VERSION "HIPFNNYYYYYYYYYYYYYYYYYYYYYYYYYYNNNNNNNNNN/4/%%%/4/'%**4NNN///"

NS_ :

BS_:

BU_: DisplayPanel GalleyMaster SteamOven CoffeeMaker TrashCompactor
VAL_TABLE_ DIAG_GenErrId_Values 0 "No error" 1 "Hardware" 2 "Software" 3 "Operation" 4 "Interface" 5 "Communication" 6 "External Resources" ;
VAL_TABLE_ DIAG_ErrGravity_Values 5 "Safety" 4 "Failure" 3 "Malfunction" 2 "Warning" 1 "Info" ;
VAL_TABLE_ DIAG_Cmd_Values 4 "SendGAIN_CLASS_msg" 2 "AbortSelfTest" 1 "SelfTestRequest" 0 "NotApplicable" ;
VAL_TABLE_ STO_FlightPhase_Values 12 "Parking/Post-flight" 11 "Taxi in" 10 "Landing" 9 "Approach" 8 "Cruise" 7 "Climb 2nd step" 6 "Climb 1st step" 5 "Take off 3rd step" 4 "Take off 2nd step" 3 "Take off 1st step" 2 "Taxi out" 1 "Parking/Pre-flight" 0 "NotApplicable" ;
VAL_TABLE_ STO_Units_Values 13 "Unit/-s" 12 "Lartge Cup/-s" 11 "Medium Cup/-s" 10 "Little Cup/-s" 9 "Flashes" 8 "Meal/-s" 7 "Fluid Ounces" 6 "Pints" 5 "Gallons" 4 "Liter" 3 "Pound" 2 "Ounces" 1 "kg" 0 "NotApplicable" ;
VAL_TABLE_ STO_Quality_Value 4 "Damaged" 3 "Low" 2 "Medium" 1 "High" 0 "Not applicable" ;
VAL_TABLE_ CSTA_NewState_Value 9 "StandBy Off" 8 "Error" 7 "Maintenance" 6 "Finished" 2 "StandBy On" ;
VAL_TABLE_ CMD_Cmd_Values 22 "Send_GAIN_Class_Msg" 21 "Send_STO_Msg" 20 "Send_CAT_Info_Msg" 4 "Keep warm" 3 "Pause catering process" 2 "Finish catering process" 1 "Start catering process" 0 "Not applicable" ;
VAL_TABLE_ STA_MGCU_StateVal 4 "Error" 3 "Maintenance" 2 "Operational" ;
VAL_TABLE_ AR812MsgCode 28 "STA_GAIN" 26 "STA_MGCU" 24 "DTA" 22 "DIAG" 20 "DIAG_CMD" 18 "PBM" 16 "PBR" 14 "GAIN_PT" 12 "FLIGHT_INFO" 10 "GAIN_CLASS" 8 "STO" 6 "CAT_INFO" 4 "CSTA" 2 "CMD" ;
VAL_TABLE_ DIAG_SpecErrId_Values 50 "Pin programming error" 43 "Phase C loss" 42 "Phase B loss" 41 "Phase A loss" 40 "Phase loss" 31 "Configuration error" 30 "Self-test aborted" 24 "Overflow" 23 "Message sequence interrupted" 22 "Command error" 21 "Invalid message" 20 "Invalid device ID" 15 "Checksum error" 14 "Data transfer denied (already on process)" 13 "File already exists" 12 "Allocation exceeded" 11 "Data transmission counter error" 10 "Data transmission interrupted" 2 "Catering Process Quality Damaged" 1 "Undefined Error" 0 "No error" ;

BO_ 3221225472 VECTOR__INDEPENDENT_SIG_MSG: 0 Vector__XXX
 SG_ PBR_BudgetType : 0|1@1+ (1,0) [0|0] "" Vector__XXX
 SG_ PBR_NominalPB : 0|8@1+ (50,0) [0|12750] "VA" Vector__XXX
 SG_ PBR_NeededTimeWithNominalPB : 0|16@1+ (1,0) [0|0] "sec" Vector__XXX
 SG_ PBR_MinPB : 0|8@1+ (50,0) [0|12750] "VA" Vector__XXX
 SG_ PBR_NeededTimeWithMinPB : 0|16@1+ (1,0) [0|0] "sec" Vector__XXX
 SG_ STA_GAIN_Mode : 0|4@1+ (1,0) [0|0] "" Vector__XXX
 SG_ STA_GAIN_State : 0|4@1+ (1,0) [0|0] "" Vector__XXX
 SG_ STA_GAIN_UsedPB : 0|8@1+ (50,0) [0|12750] "" Vector__XXX
 SG_ STA_GAIN_FallbackPB : 0|8@1+ (1,0) [0|0] "" Vector__XXX
 SG_ STA_GAIN_PBRemainingTime : 0|16@1+ (1,0) [0|0] "" Vector__XXX
 SG_ STA_GAIN_ImplFunc : 0|8@1+ (1,0) [0|0] "" Vector__XXX
 SG_ STA_GAIN_PBudgetType : 0|1@1+ (1,0) [0|0] "" Vector__XXX
 SG_ STA_GAIN_FlightInfoRcvd : 0|1@1+ (1,0) [0|0] "" Vector__XXX
 SG_ STA_GAIN_Mode : 0|4@1+ (1,0) [0|0] "" Vector__XXX
 SG_ STA_GAIN_State : 0|4@1+ (1,0) [0|0] "" Vector__XXX
 SG_ STA_GAIN_UsedPB : 0|8@1+ (50,0) [0|12750] "" Vector__XXX
 SG_ STA_GAIN_FallbackPB : 0|8@1+ (1,0) [0|0] "" Vector__XXX
 SG_ STA_GAIN_PBRemainingTime : 0|16@1+ (1,0) [0|0] "" Vector__XXX
 SG_ STA_GAIN_ImplFunc : 0|8@1+ (1,0) [0|0] "" Vector__XXX
 SG_ STA_GAIN_PBudgetType : 0|1@1+ (1,0) [0|0] "" Vector__XXX
 SG_ STA_GAIN_FlightInfoRcvd : 0|1@1+ (1,0) [0|0] "" Vector__XXX
 SG_ STA_MGCU_State : 0|8@1+ (1,0) [0|0] "" Vector__XXX
 SG_ STA_MGCU_Impl_Func : 0|8@1+ (1,0) [0|0] "" Vector__XXX
 SG_ STA_MGCU_Power_Info_Feeder : 0|5@1+ (1,0) [0|0] "" Vector__XXX
 SG_ STA_MGCU_Power_Info : 0|11@1+ (1,0) [0|0] "" Vector__XXX
 SG_ STA_MGCU_Pwr_Cntrl_Prio : 0|2@1+ (1,0) [0|0] "" Vector__XXX
 SG_ DTA_Descr_DataPacketNr : 0|4@1- (1,0) [0|15] "" Vector__XXX
 SG_ DTA_Descr_HandshakeType : 0|4@1+ (1,0) [0|15] "" Vector__XXX
 SG_ DTA_SrcLevelId : 0|5@1+ (1,0) [0|0] "" Vector__XXX
 SG_ DTA_SrcDeviceId : 0|5@1+ (1,0) [0|0] "" Vector__XXX
 SG_ DTA_Descr_Type : 0|1@1+ (1,0) [0|1] "" Vector__XXX
 SG_ DIAG_Counter : 0|4@1+ (1,0) [0|0] "" Vector__XXX
 SG_ DIAG_ErrGravity : 0|3@1+ (1,0) [0|0] "" Vector__XXX
 SG_ DIAG_GenErrId : 0|8@1+ (1,0) [0|0] "" Vector__XXX
 SG_ DIAG_SpecErrId : 0|8@1+ (1,0) [0|0] "" Vector__XXX
 SG_ DIAG_VendorErrId : 0|8@1+ (1,0) [0|0] "" Vector__XXX
 SG_ DIAG_CMD_Cmd : 0|8@1+ (1,0) [0|0] "" Vector__XXX
 SG_ PBR_BudgetType : 0|1@1+ (1,0) [0|0] "" Vector__XXX
 SG_ PBR_NominalPB : 0|8@1+ (50,0) [0|12750] "VA" Vector__XXX
 SG_ PBR_NeededTimeWithNominalPB : 0|16@1+ (1,0) [0|0] "sec" Vector__XXX
 SG_ PBR_MinPB : 0|8@1+ (50,0) [0|12750] "VA" Vector__XXX
 SG_ PBR_NeededTimeWithMinPB : 0|16@1+ (1,0) [0|0] "sec" Vector__XXX
 SG_ GAIN_PT_StandByPt : 0|8@1+ (5,0) [0|1275] "VA" Vector__XXX
 SG_ GAIN_PT_MaxPt : 0|8@1+ (50,0) [0|0] "VA" Vector__XXX
 SG_ GAIN_PT_MinPt : 0|8@1+ (50,0) [0|12750] "VA" Vector__XXX
 SG_ GAIN_PT_FallBackPt : 0|8@1+ (50,0) [0|12750] "VA" Vector__XXX
 SG_ FLIGHT_INFO_Year : 0|8@1+ (1,2000) [2000|2255] "" Vector__XXX
 SG_ FLIGHT_INFO_Month : 0|4@1+ (1,0) [0|0] "" Vector__XXX
 SG_ FLIGHT_INFO_Day : 0|5@1+ (1,0) [0|0] "" Vector__XXX
 SG_ FLIGHT_INFO_Hour : 0|5@1+ (1,0) [0|0] "" Vector__XXX
 SG_ FLIGHT_INFO_Min : 0|6@1+ (1,0) [0|0] "" Vector__XXX
 SG_ FLIGHT_INFO_Sec : 0|5@1+ (1,0) [0|0] "" Vector__XXX
 SG_ FLIGHT_INFO_FlightPhase : 0|4@1+ (1,0) [0|0] "" Vector__XXX
 SG_ GAIN_CLASS_DevClass : 0|5@1+ (1,0) [0|0] "" Vector__XXX
 SG_ GAIN_CLASS_DevGroup : 0|5@1+ (1,0) [0|0] "" Vector__XXX
 SG_ STO_Quality : 0|3@1+ (1,0) [0|0] "" Vector__XXX
 SG_ STO_Units : 0|5@1+ (1,0) [0|31] "" Vector__XXX
 SG_ STO_Quantity : 0|8@1+ (1,0) [0|0] "" Vector__XXX
 SG_ STO_FoodTypeDescr1 : 0|8@1+ (1,0) [0|0] "" Vector__XXX
 SG_ STO_FoodTypeDescr2 : 0|8@1+ (1,0) [0|0] "" Vector__XXX
 SG_ STO_FoodTypeDescr3 : 0|8@1+ (1,0) [0|0] "" Vector__XXX
 SG_ STO_FoodTypeDescr4 : 0|8@1+ (1,0) [0|0] "" Vector__XXX
 SG_ STO_Cluster : 0|4@1+ (1,0) [0|0] "" Vector__XXX
 SG_ CAT_Info_CateringProcess : 0|8@1+ (1,0) [0|0] "" Vector__XXX
 SG_ CAT_Info_SelectCaterProgram : 0|5@1+ (1,0) [0|0] "" Vector__XXX
 SG_ CAT_Info_PhysUnit : 0|3@1+ (1,0) [0|0] "" Vector__XXX
 SG_ CAT_Info_PhysUnit : 0|3@1+ (1,0) [0|0] "" Vector__XXX
 SG_ CAT_Info_PhysProp1 : 0|16@1+ (1,0) [0|0] "" Vector__XXX
 SG_ CAT_Info_PhysProp1 : 0|16@1+ (1,0) [0|0] "" Vector__XXX
 SG_ CAT_Info_Cluster : 0|4@1+ (1,0) [0|0] "" Vector__XXX
 SG_ CSTA_Reset : 0|1@1+ (1,0) [0|0] "" Vector__XXX
 SG_ CSTA_PowerCntrlMode : 0|3@1+ (1,0) [0|0] "" Vector__XXX
 SG_ CSTA_NewState : 0|4@1+ (1,0) [0|0] "" Vector__XXX
 SG_ CMD_Command : 0|5@1+ (1,0) [0|0] "" Vector__XXX
 SG_ CMD_SetCateringProgram : 0|5@1+ (1,0) [0|0] "" Vector__XXX
 SG_ CMD_PhysUnit1 : 0|3@1+ (1,0) [0|0] "" Vector__XXX
 SG_ CMD_PhysUnit2 : 0|3@1+ (1,0) [0|0] "" Vector__XXX
 SG_ CMD_PhysProperty1 : 0|16@1+ (1,0) [0|0] "" Vector__XXX
 SG_ CMD_PhysProperty2 : 0|16@1+ (1,0) [0|0] "" Vector__XXX
 SG_ CMD_Cluster : 0|4@1+ (1,0) [0|0] "" Vector__XXX

BO_ 2358265349 PBM_ToTrashCompactor: 8 Vector__XXX
 SG_ PBM_PBMax : 0|8@1+ (50,0) [0|12750] "VA" Vector__XXX
 SG_ PBM_Time : 8|16@1+ (1,0) [0|0] "" Vector__XXX

BO_ 2358264837 PBM_ToSteamOven: 8 Vector__XXX
 SG_ PBM_PBMax : 0|8@1+ (50,0) [0|12750] "VA" Vector__XXX
 SG_ PBM_Time : 8|16@1+ (1,0) [0|0] "" Vector__XXX

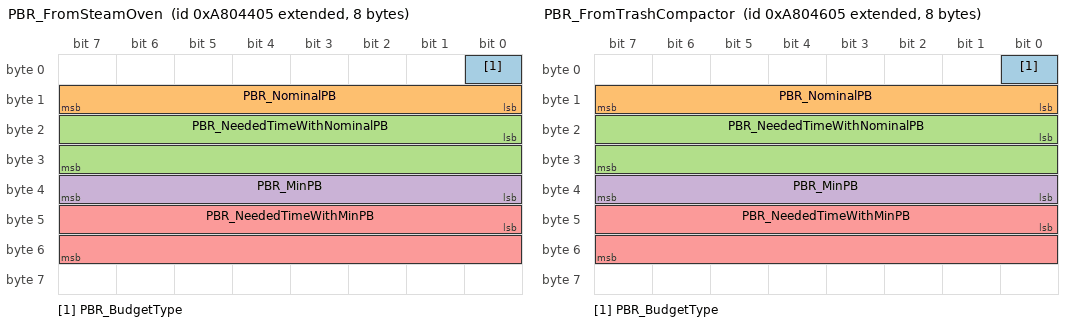
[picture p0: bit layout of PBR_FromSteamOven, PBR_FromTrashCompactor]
BO_ 2323661829 PBR_FromSteamOven: 8 Vector__XXX
 SG_ PBR_BudgetType : 0|1@1+ (1,0) [0|0] "" Vector__XXX
 SG_ PBR_NominalPB : 8|8@1+ (50,0) [0|12750] "VA" Vector__XXX
 SG_ PBR_NeededTimeWithNominalPB : 16|16@1+ (1,0) [0|0] "sec" Vector__XXX
 SG_ PBR_MinPB : 32|8@1+ (50,0) [0|12750] "VA" Vector__XXX
 SG_ PBR_NeededTimeWithMinPB : 40|16@1+ (1,0) [0|0] "sec" Vector__XXX

BO_ 2323662341 PBR_FromTrashCompactor: 8 Vector__XXX
 SG_ PBR_BudgetType : 0|1@1+ (1,0) [0|0] "" Vector__XXX
 SG_ PBR_NominalPB : 8|8@1+ (50,0) [0|12750] "VA" Vector__XXX
 SG_ PBR_NeededTimeWithNominalPB : 16|16@1+ (1,0) [0|0] "sec" Vector__XXX
 SG_ PBR_MinPB : 32|8@1+ (50,0) [0|12750] "VA" Vector__XXX
 SG_ PBR_NeededTimeWithMinPB : 40|16@1+ (1,0) [0|0] "sec" Vector__XXX

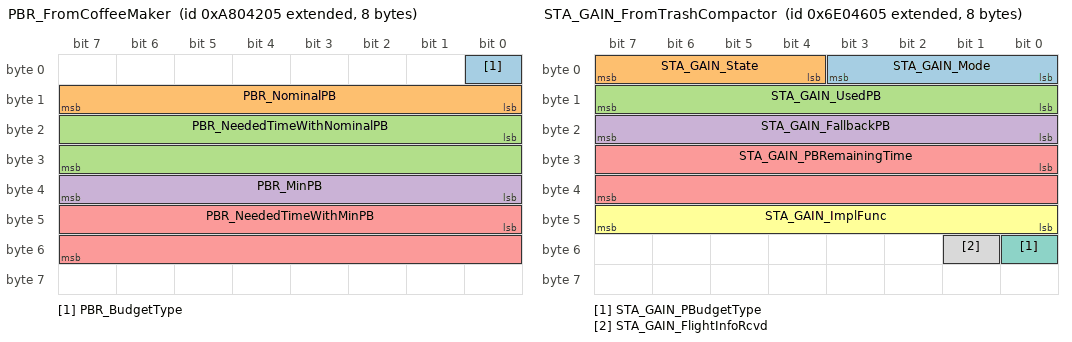
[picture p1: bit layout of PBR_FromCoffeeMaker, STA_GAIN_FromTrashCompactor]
BO_ 2323661317 PBR_FromCoffeeMaker: 8 Vector__XXX
 SG_ PBR_BudgetType : 0|1@1+ (1,0) [0|0] "" Vector__XXX
 SG_ PBR_NominalPB : 8|8@1+ (50,0) [0|12750] "VA" Vector__XXX
 SG_ PBR_NeededTimeWithNominalPB : 16|16@1+ (1,0) [0|0] "sec" Vector__XXX
 SG_ PBR_MinPB : 32|8@1+ (50,0) [0|12750] "VA" Vector__XXX
 SG_ PBR_NeededTimeWithMinPB : 40|16@1+ (1,0) [0|0] "sec" Vector__XXX

BO_ 2262844933 STA_GAIN_FromTrashCompactor: 8 TrashCompactor
 SG_ STA_GAIN_Mode : 0|4@1+ (1,0) [0|0] "" Vector__XXX
 SG_ STA_GAIN_State : 4|4@1+ (1,0) [0|0] "" Vector__XXX
 SG_ STA_GAIN_UsedPB : 8|8@1+ (50,0) [0|12750] "" Vector__XXX
 SG_ STA_GAIN_FallbackPB : 16|8@1+ (1,0) [0|0] "" Vector__XXX
 SG_ STA_GAIN_PBRemainingTime : 24|16@1+ (1,0) [0|0] "" Vector__XXX
 SG_ STA_GAIN_ImplFunc : 40|8@1+ (1,0) [0|0] "" Vector__XXX
 SG_ STA_GAIN_PBudgetType : 48|1@1+ (1,0) [0|0] "" Vector__XXX
 SG_ STA_GAIN_FlightInfoRcvd : 49|1@1+ (1,0) [0|0] "" Vector__XXX

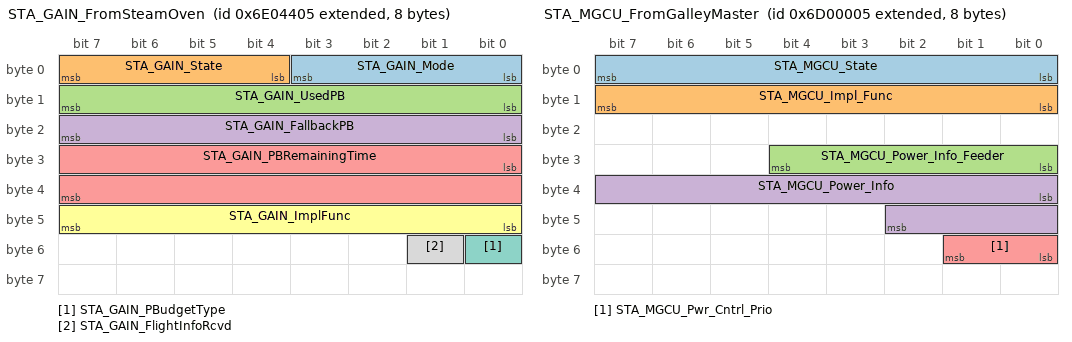
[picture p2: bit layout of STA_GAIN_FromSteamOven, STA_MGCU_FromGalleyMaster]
BO_ 2262844421 STA_GAIN_FromSteamOven: 8 SteamOven
 SG_ STA_GAIN_Mode : 0|4@1+ (1,0) [0|0] "" Vector__XXX
 SG_ STA_GAIN_State : 4|4@1+ (1,0) [0|0] "" Vector__XXX
 SG_ STA_GAIN_UsedPB : 8|8@1+ (50,0) [0|12750] "" Vector__XXX
 SG_ STA_GAIN_FallbackPB : 16|8@1+ (1,0) [0|0] "" Vector__XXX
 SG_ STA_GAIN_PBRemainingTime : 24|16@1+ (1,0) [0|0] "" Vector__XXX
 SG_ STA_GAIN_ImplFunc : 40|8@1+ (1,0) [0|0] "" Vector__XXX
 SG_ STA_GAIN_PBudgetType : 48|1@1+ (1,0) [0|0] "" Vector__XXX
 SG_ STA_GAIN_FlightInfoRcvd : 49|1@1+ (1,0) [0|0] "" Vector__XXX

BO_ 2261778437 STA_MGCU_FromGalleyMaster: 8 GalleyMaster
 SG_ STA_MGCU_State : 0|8@1+ (1,0) [0|0] "" Vector__XXX
 SG_ STA_MGCU_Impl_Func : 8|8@1+ (1,0) [0|0] "" Vector__XXX
 SG_ STA_MGCU_Power_Info_Feeder : 24|5@1+ (1,0) [0|0] "" Vector__XXX
 SG_ STA_MGCU_Power_Info : 32|11@1+ (1,0) [0|0] "" Vector__XXX
 SG_ STA_MGCU_Pwr_Cntrl_Prio : 48|2@1+ (1,0) [0|0] "" Vector__XXX

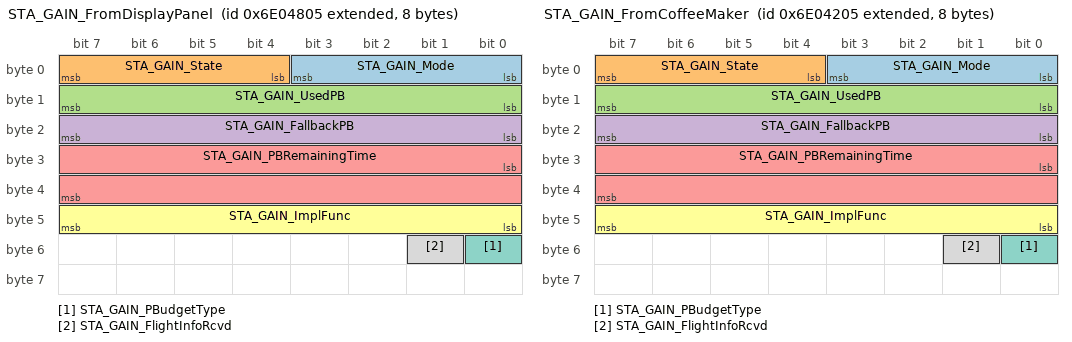
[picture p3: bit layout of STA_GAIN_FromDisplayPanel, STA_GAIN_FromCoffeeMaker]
BO_ 2262845445 STA_GAIN_FromDisplayPanel: 8 DisplayPanel
 SG_ STA_GAIN_Mode : 0|4@1+ (1,0) [0|0] "" Vector__XXX
 SG_ STA_GAIN_State : 4|4@1+ (1,0) [0|0] "" Vector__XXX
 SG_ STA_GAIN_UsedPB : 8|8@1+ (50,0) [0|12750] "" Vector__XXX
 SG_ STA_GAIN_FallbackPB : 16|8@1+ (1,0) [0|0] "" Vector__XXX
 SG_ STA_GAIN_PBRemainingTime : 24|16@1+ (1,0) [0|0] "" Vector__XXX
 SG_ STA_GAIN_ImplFunc : 40|8@1+ (1,0) [0|0] "" Vector__XXX
 SG_ STA_GAIN_PBudgetType : 48|1@1+ (1,0) [0|0] "" Vector__XXX
 SG_ STA_GAIN_FlightInfoRcvd : 49|1@1+ (1,0) [0|0] "" Vector__XXX

BO_ 2262843909 STA_GAIN_FromCoffeeMaker: 8 CoffeeMaker
 SG_ STA_GAIN_Mode : 0|4@1+ (1,0) [0|0] "" Vector__XXX
 SG_ STA_GAIN_State : 4|4@1+ (1,0) [0|0] "" Vector__XXX
 SG_ STA_GAIN_UsedPB : 8|8@1+ (50,0) [0|12750] "" Vector__XXX
 SG_ STA_GAIN_FallbackPB : 16|8@1+ (1,0) [0|0] "" Vector__XXX
 SG_ STA_GAIN_PBRemainingTime : 24|16@1+ (1,0) [0|0] "" Vector__XXX
 SG_ STA_GAIN_ImplFunc : 40|8@1+ (1,0) [0|0] "" Vector__XXX
 SG_ STA_GAIN_PBudgetType : 48|1@1+ (1,0) [0|0] "" Vector__XXX
 SG_ STA_GAIN_FlightInfoRcvd : 49|1@1+ (1,0) [0|0] "" Vector__XXX

BO_ 2358264325 PBM_ToCoffeeMaker: 8 Vector__XXX
 SG_ PBM_PBMax : 0|8@1+ (50,0) [0|12750] "VA" Vector__XXX
 SG_ PBM_Time : 8|16@1+ (1,0) [0|0] "" Vector__XXX

EV_ SteamOven_PowerUsed: 0 [0|0] "" 0 1 DUMMY_NODE_VECTOR0 Vector__XXX;

EV_ CoffeeMaker_PowerUsed: 0 [0|0] "" 0 2 DUMMY_NODE_VECTOR0 Vector__XXX;

EV_ CoffeeMaker_TempCurrent: 1 [0|0] "" 0 3 DUMMY_NODE_VECTOR0 Vector__XXX;

EV_ SteamOven_TimeText: 0 [0|0] "" 0 4 DUMMY_NODE_VECTOR8000 Vector__XXX;

EV_ SteamOven_TempCurrent: 1 [0|0] "" 0 5 DUMMY_NODE_VECTOR0 Vector__XXX;

EV_ SteamOven_Time: 0 [0|0] "" 0 6 DUMMY_NODE_VECTOR0 Vector__XXX;

EV_ SteamOven_Insert: 0 [0|0] "" 0 7 DUMMY_NODE_VECTOR0 Vector__XXX;

EV_ TrashCompactor_Insert: 0 [0|0] "" 0 8 DUMMY_NODE_VECTOR0 Vector__XXX;

EV_ CoffeeMaker_Insert: 0 [0|0] "" 0 9 DUMMY_NODE_VECTOR0 Vector__XXX;

EV_ TrashCompactor_Trash: 0 [0|0] "" 0 10 DUMMY_NODE_VECTOR0 Vector__XXX;

EV_ SteamOven_Meal: 0 [0|0] "" 0 11 DUMMY_NODE_VECTOR0 Vector__XXX;

EV_ CoffeeMaker_Pot: 0 [0|0] "" 0 12 DUMMY_NODE_VECTOR0 Vector__XXX;

EV_ TrashCompactor_Device: 0 [0|0] "" 0 13 DUMMY_NODE_VECTOR0 Vector__XXX;

EV_ TrashCompactor_Feeder: 0 [0|0] "" 0 14 DUMMY_NODE_VECTOR0 Vector__XXX;

EV_ SteamOven_Device: 0 [0|0] "" 0 15 DUMMY_NODE_VECTOR0 Vector__XXX;

EV_ SteamOven_Feeder: 0 [0|0] "" 0 16 DUMMY_NODE_VECTOR0 Vector__XXX;

EV_ DisplayPanel_Device: 0 [0|0] "" 0 17 DUMMY_NODE_VECTOR0 Vector__XXX;

EV_ DisplayPanel_Feeder: 0 [0|0] "" 0 18 DUMMY_NODE_VECTOR0 Vector__XXX;

EV_ CoffeeMaker_Device: 0 [0|0] "" 0 19 DUMMY_NODE_VECTOR0 Vector__XXX;

EV_ CoffeeMaker_Feeder: 0 [0|0] "" 0 20 DUMMY_NODE_VECTOR0 Vector__XXX;

EV_ DisplayPanel_Esc: 0 [0|0] "" 0 21 DUMMY_NODE_VECTOR0 Vector__XXX;

EV_ DisplayPanel_OK: 0 [0|0] "" 0 22 DUMMY_NODE_VECTOR0 Vector__XXX;

EV_ DisplayPanel_Next: 0 [0|0] "" 0 23 DUMMY_NODE_VECTOR0 Vector__XXX;

EV_ DisplayPanel_Back: 0 [0|0] "" 0 24 DUMMY_NODE_VECTOR0 Vector__XXX;

EV_ DisplayPanel_Out: 0 [0|0] "" 0 25 DUMMY_NODE_VECTOR8000 Vector__XXX;

EV_ CoffeeMaker_ColdWater: 0 [0|0] "" 0 26 DUMMY_NODE_VECTOR0 Vector__XXX;

EV_ CoffeeMaker_HotWater: 0 [0|0] "" 0 27 DUMMY_NODE_VECTOR0 Vector__XXX;

EV_ CoffeeMaker_HotPlateOn: 0 [0|0] "" 0 28 DUMMY_NODE_VECTOR0 Vector__XXX;

EV_ CoffeeMaker_Brew: 0 [0|0] "" 0 29 DUMMY_NODE_VECTOR0 Vector__XXX;

EV_ CoffeeMaker_Power: 0 [0|0] "" 0 30 DUMMY_NODE_VECTOR0 Vector__XXX;

EV_ CoffeeMaker_Fault: 0 [0|0] "" 0 31 DUMMY_NODE_VECTOR0 Vector__XXX;

EV_ CoffeeMaker_Serve: 0 [0|0] "" 0 32 DUMMY_NODE_VECTOR0 Vector__XXX;

EV_ CoffeeMaker_On: 0 [0|0] "" 0 33 DUMMY_NODE_VECTOR0 Vector__XXX;

EV_ SteamOven_Temp: 0 [0|0] "" 50 34 DUMMY_NODE_VECTOR0 Vector__XXX;

EV_ SteamOven_Power: 0 [0|0] "" 0 35 DUMMY_NODE_VECTOR0 Vector__XXX;

EV_ SteamOven_Fault: 0 [0|0] "" 0 36 DUMMY_NODE_VECTOR0 Vector__XXX;

EV_ SteamOven_Serve: 0 [0|0] "" 0 37 DUMMY_NODE_VECTOR0 Vector__XXX;

EV_ SteamOven_On: 0 [0|0] "" 0 38 DUMMY_NODE_VECTOR0 Vector__XXX;

EV_ TrashCompactor_Power: 0 [0|0] "" 0 39 DUMMY_NODE_VECTOR0 Vector__XXX;

EV_ TrashCompactor_Warning: 0 [0|0] "" 0 40 DUMMY_NODE_VECTOR0 Vector__XXX;

EV_ TrashCompactor_Fault: 0 [0|0] "" 0 41 DUMMY_NODE_VECTOR0 Vector__XXX;

EV_ TrashCompactor_On: 0 [0|0] "" 0 42 DUMMY_NODE_VECTOR0 Vector__XXX;

CM_ BO_ 3221225472 "This is a message for not used signals, created by Vector CANdb++ DBC OLE DB Provider.";
BA_DEF_ BU_  "GAINCFG12_1_2_GAIN_COUNTER_THRES" HEX 0 255;
BA_DEF_ BU_  "GAINCFG12_1_1_GAIN_COUNTER_DELTA" HEX 0 255;
BA_DEF_ BU_  "GAINCFG12_1_0_GAIN_COUNTER_DELTA" HEX 0 255;
BA_DEF_ BU_  "MGCUCFG12_0_2_MGCU_COUNTER_THRES" HEX 0 255;
BA_DEF_ BU_  "MGCUCFG12_0_1_MGCU_COUNTER_DELTA" HEX 0 255;
BA_DEF_ BU_  "MGCUCFG12_0_0_MGCU_COUNTER_DELTA" HEX 0 255;
BA_DEF_ BU_  "GAINCFG11_1_1_DECENTRALIZED_RAND" HEX 0 65535;
BA_DEF_ BU_  "GAINCFG11_1_0_DECENTRALIZED_RAND" HEX 0 65535;
BA_DEF_ BU_  "GAINCFG11_0_1_DECENTRALIZED_SYNC" HEX 0 65535;
BA_DEF_ BU_  "GAINCFG11_0_0_DECENTRALIZED_SYNC" HEX 0 65535;
BA_DEF_ BU_  "MGCUCFG10_8_2_INHIBIT_TIMER_STA_" HEX 0 65535;
BA_DEF_ BU_  "MGCUCFG10_8_1_TIMER_STA_TIMEOUT_" HEX 0 65535;
BA_DEF_ BU_  "MGCUCFG10_8_0_TIMER_STA_MGCU" HEX 0 65535;
BA_DEF_ BU_  "MGCUCFG10_7_0_INHIBIT_TIMER_DIAG" HEX 0 65535;
BA_DEF_ BU_  "MGCUCFG10_6_0_INHIBIT_TIMER_PBM" HEX 0 65535;
BA_DEF_ BU_  "MGCUCFG10_5_0_INHIBIT_TIMER_FLIG" HEX 0 65535;
BA_DEF_ BU_  "MGCUCFG10_4_0_INHIBIT_TIMER_CSTA" HEX 0 65535;
BA_DEF_ BU_  "MGCUCFG10_3_0_INHIBIT_TIMER_CMD" HEX 0 65535;
BA_DEF_ BU_  "MGCUCFG10_2_0_SEQUENCE_TIMEOUT_T" HEX 0 65535;
BA_DEF_ BU_  "MGCUCFG10_1_0_INHIBIT_TIMER_DTA" HEX 0 65535;
BA_DEF_ BU_  "MGCUCFG10_0_0_INHIBIT_TIMER_DIAG" HEX 0 65535;
BA_DEF_ BU_  "GAINCFG9_9_2_INHIBIT_TIMER_STA_G" HEX 0 65535;
BA_DEF_ BU_  "GAINCFG9_9_1_TIMER_STA_TIMEOUT_G" HEX 0 65535;
BA_DEF_ BU_  "GAINCFG9_9_0_TIMER_STA_GAIN" HEX 0 65535;
BA_DEF_ BU_  "GAINCFG9_8_0_INHIBIT_TIMER_PBR" HEX 0 65535;
BA_DEF_ BU_  "GAINCFG9_7_0_INHIBIT_TIMER_GAIN_" HEX 0 65535;
BA_DEF_ BU_  "GAINCFG9_6_0_FLIGHT_INFO_RECEIVE" HEX 0 65535;
BA_DEF_ BU_  "GAINCFG9_5_0_INHIBIT_TIMER_GAIN_" HEX 0 65535;
BA_DEF_ BU_  "GAINCFG9_4_0_INHIBIT_TIMER_STO" HEX 0 65535;
BA_DEF_ BU_  "GAINCFG9_3_0_INHIBIT_TIMER_CAT_I" HEX 0 65535;
BA_DEF_ BU_  "GAINCFG9_2_0_SEQUENCE_TIMEOUT_TI" HEX 0 65535;
BA_DEF_ BU_  "GAINCFG7_X_6_SIGN_PHYSICAL_UNIT_" ENUM  "plus","minus";
BA_DEF_ BU_  "GAINCFG7_X_3_SIGN_PHYSICAL_UNIT_" ENUM  "plus","minus";
BA_DEF_ BU_  "GAINCFG5_3_0_DEVICE_CLASS" ENUM  "Specific (Other)","Oven","Beverage Maker","Refrigerator","Waste Handling","Reserved";
BA_DEF_ BU_  "GAINCFG5_2_0_DEVICE_NUMBER" HEX 0 31;
BA_DEF_ BU_  "GAINCFG5_1_0_FEEDER_NUMBER" HEX 0 31;
BA_DEF_ BU_  "GAINCFG5_0_0_FALLBACK_TYPE" ENUM  "Secondary","Primary";
BA_DEF_ BU_  "GAINCFG3_3_0_STANDBY_POWER_THRES" INT 0 12750;
BA_DEF_ BU_  "GAINCFG3_2_0_MINIMUM_POWER_BUDGE" INT 0 12750;
BA_DEF_ BU_  "GAINCFG3_1_0_FALLBACK_POWER_THRE" INT 0 12750;
BA_DEF_ BU_  "GAINCFG3_0_0_MAXIMUM_POWER_BUDGE" INT 0 12750;
BA_DEF_ BU_  "CFG2_1_0_CENTRALIZED_POWER_CONTR" ENUM  "no","yes";
BA_DEF_ BU_  "GAINCFG1_0_0_DEVICE_STANDARD" ENUM  "Reserved","ARINC","ATLAS","KSSU","Reserved","Reserved","Reserved","Reserved","Reserved","Reserved","Reserved","Reserved","Reserved","Reserved","Reserved","Reserved";
BA_DEF_  "ProtocolType" STRING ;
BA_DEF_  "BusType" STRING ;
BA_DEF_DEF_  "GAINCFG12_1_2_GAIN_COUNTER_THRES" 1;
BA_DEF_DEF_  "GAINCFG12_1_1_GAIN_COUNTER_DELTA" 1;
BA_DEF_DEF_  "GAINCFG12_1_0_GAIN_COUNTER_DELTA" 1;
BA_DEF_DEF_  "MGCUCFG12_0_2_MGCU_COUNTER_THRES" 1;
BA_DEF_DEF_  "MGCUCFG12_0_1_MGCU_COUNTER_DELTA" 1;
BA_DEF_DEF_  "MGCUCFG12_0_0_MGCU_COUNTER_DELTA" 1;
BA_DEF_DEF_  "GAINCFG11_1_1_DECENTRALIZED_RAND" 200;
BA_DEF_DEF_  "GAINCFG11_1_0_DECENTRALIZED_RAND" 50;
BA_DEF_DEF_  "GAINCFG11_0_1_DECENTRALIZED_SYNC" 1000;
BA_DEF_DEF_  "GAINCFG11_0_0_DECENTRALIZED_SYNC" 1000;
BA_DEF_DEF_  "MGCUCFG10_8_2_INHIBIT_TIMER_STA_" 1000;
BA_DEF_DEF_  "MGCUCFG10_8_1_TIMER_STA_TIMEOUT_" 2200;
BA_DEF_DEF_  "MGCUCFG10_8_0_TIMER_STA_MGCU" 2000;
BA_DEF_DEF_  "MGCUCFG10_7_0_INHIBIT_TIMER_DIAG" 1000;
BA_DEF_DEF_  "MGCUCFG10_6_0_INHIBIT_TIMER_PBM" 1000;
BA_DEF_DEF_  "MGCUCFG10_5_0_INHIBIT_TIMER_FLIG" 1000;
BA_DEF_DEF_  "MGCUCFG10_4_0_INHIBIT_TIMER_CSTA" 1000;
BA_DEF_DEF_  "MGCUCFG10_3_0_INHIBIT_TIMER_CMD" 1000;
BA_DEF_DEF_  "MGCUCFG10_2_0_SEQUENCE_TIMEOUT_T" 5000;
BA_DEF_DEF_  "MGCUCFG10_1_0_INHIBIT_TIMER_DTA" 50;
BA_DEF_DEF_  "MGCUCFG10_0_0_INHIBIT_TIMER_DIAG" 1000;
BA_DEF_DEF_  "GAINCFG9_9_2_INHIBIT_TIMER_STA_G" 1000;
BA_DEF_DEF_  "GAINCFG9_9_1_TIMER_STA_TIMEOUT_G" 2200;
BA_DEF_DEF_  "GAINCFG9_9_0_TIMER_STA_GAIN" 2000;
BA_DEF_DEF_  "GAINCFG9_8_0_INHIBIT_TIMER_PBR" 1000;
BA_DEF_DEF_  "GAINCFG9_7_0_INHIBIT_TIMER_GAIN_" 1000;
BA_DEF_DEF_  "GAINCFG9_6_0_FLIGHT_INFO_RECEIVE" 6200;
BA_DEF_DEF_  "GAINCFG9_5_0_INHIBIT_TIMER_GAIN_" 6000;
BA_DEF_DEF_  "GAINCFG9_4_0_INHIBIT_TIMER_STO" 6000;
BA_DEF_DEF_  "GAINCFG9_3_0_INHIBIT_TIMER_CAT_I" 1000;
BA_DEF_DEF_  "GAINCFG9_2_0_SEQUENCE_TIMEOUT_TI" 5000;
BA_DEF_DEF_  "GAINCFG7_X_6_SIGN_PHYSICAL_UNIT_" "plus";
BA_DEF_DEF_  "GAINCFG7_X_3_SIGN_PHYSICAL_UNIT_" "plus";
BA_DEF_DEF_  "GAINCFG5_3_0_DEVICE_CLASS" "Specific (Other)";
BA_DEF_DEF_  "GAINCFG5_2_0_DEVICE_NUMBER" 0;
BA_DEF_DEF_  "GAINCFG5_1_0_FEEDER_NUMBER" 0;
BA_DEF_DEF_  "GAINCFG5_0_0_FALLBACK_TYPE" "Secondary";
BA_DEF_DEF_  "GAINCFG3_3_0_STANDBY_POWER_THRES" 0;
BA_DEF_DEF_  "GAINCFG3_2_0_MINIMUM_POWER_BUDGE" 0;
BA_DEF_DEF_  "GAINCFG3_1_0_FALLBACK_POWER_THRE" 0;
BA_DEF_DEF_  "GAINCFG3_0_0_MAXIMUM_POWER_BUDGE" 0;
BA_DEF_DEF_  "CFG2_1_0_CENTRALIZED_POWER_CONTR" "no";
BA_DEF_DEF_  "GAINCFG1_0_0_DEVICE_STANDARD" "ARINC";
BA_DEF_DEF_  "ProtocolType" "ARINC812";
BA_DEF_DEF_  "BusType" "CAN";
BA_ "GAINCFG5_2_0_DEVICE_NUMBER" BU_ DisplayPanel 4;
BA_ "GAINCFG5_1_0_FEEDER_NUMBER" BU_ DisplayPanel 1;
BA_ "GAINCFG3_0_0_MAXIMUM_POWER_BUDGE" BU_ SteamOven 2960;
BA_ "GAINCFG3_1_0_FALLBACK_POWER_THRE" BU_ SteamOven 2960;
BA_ "GAINCFG3_2_0_MINIMUM_POWER_BUDGE" BU_ SteamOven 2960;
BA_ "GAINCFG3_3_0_STANDBY_POWER_THRES" BU_ SteamOven 20;
BA_ "GAINCFG5_2_0_DEVICE_NUMBER" BU_ SteamOven 2;
BA_ "GAINCFG5_1_0_FEEDER_NUMBER" BU_ SteamOven 1;
BA_ "GAINCFG5_3_0_DEVICE_CLASS" BU_ SteamOven 1;
BA_ "GAINCFG3_0_0_MAXIMUM_POWER_BUDGE" BU_ CoffeeMaker 3000;
BA_ "GAINCFG3_1_0_FALLBACK_POWER_THRE" BU_ CoffeeMaker 3000;
BA_ "GAINCFG3_2_0_MINIMUM_POWER_BUDGE" BU_ CoffeeMaker 3000;
BA_ "GAINCFG3_3_0_STANDBY_POWER_THRES" BU_ CoffeeMaker 120;
BA_ "GAINCFG5_2_0_DEVICE_NUMBER" BU_ CoffeeMaker 1;
BA_ "GAINCFG5_1_0_FEEDER_NUMBER" BU_ CoffeeMaker 1;
BA_ "CFG2_1_0_CENTRALIZED_POWER_CONTR" BU_ CoffeeMaker 1;
BA_ "GAINCFG3_0_0_MAXIMUM_POWER_BUDGE" BU_ TrashCompactor 2178;
BA_ "GAINCFG3_1_0_FALLBACK_POWER_THRE" BU_ TrashCompactor 2178;
BA_ "GAINCFG3_2_0_MINIMUM_POWER_BUDGE" BU_ TrashCompactor 2178;
BA_ "GAINCFG3_3_0_STANDBY_POWER_THRES" BU_ TrashCompactor 10;
BA_ "GAINCFG5_2_0_DEVICE_NUMBER" BU_ TrashCompactor 3;
BA_ "GAINCFG5_1_0_FEEDER_NUMBER" BU_ TrashCompactor 1;
BA_ "GAINCFG5_3_0_DEVICE_CLASS" BU_ TrashCompactor 4;
VAL_ 3221225472 STA_MGCU_State 4 "Error" 3 "Maintenance" 2 "Operational" ;
VAL_ 3221225472 DTA_Descr_DataPacketNr 15 "16th data packet" 14 "15th data packet" 13 "14th data packet" 12 "13th data packet" 11 "12th data packet" 10 "11th data packet" 9 "10th data packet" 8 "9th data packet" 7 "8th data packet" 6 "7th data packet" 5 "6th data packet" 4 "5th data packet" 3 "4th data packet" 2 "3rd data packet" 1 "2nd data packet" 0 "1st data packet" ;
VAL_ 3221225472 DTA_Descr_HandshakeType 10 "EOT" 9 "Abort" 8 "Retry all blocks" 7 "Retry last block" 6 "Acknowledge" 5 "RFT" 4 "AOT Download Memory mech." 3 "AOT Download Block mech." 2 "AOT Upload Memory mech." 1 "AOT Upload Block mech." 0 "Reserved" ;
VAL_ 3221225472 DTA_Descr_Type 1 "Handshake frame" 0 "Data frame" ;
VAL_ 3221225472 DIAG_ErrGravity 5 "Safety" 4 "Failure" 3 "Malfunction" 2 "Warning" 1 "Info" ;
VAL_ 3221225472 DIAG_GenErrId 0 "No error" 1 "Hardware" 2 "Software" 3 "Operation" 4 "Interface" 5 "Communication" 6 "External Resources" ;
VAL_ 3221225472 DIAG_SpecErrId 50 "Pin programming error" 43 "Phase C loss" 42 "Phase B loss" 41 "Phase A loss" 40 "Phase loss" 31 "Configuration error" 30 "Self-test aborted" 24 "Overflow" 23 "Message sequence interrupted" 22 "Command error" 21 "Invalid message" 20 "Invalid device ID" 15 "Checksum error" 14 "Data transfer denied (already on process)" 13 "File already exists" 12 "Allocation exceeded" 11 "Data transmission counter error" 10 "Data transmission interrupted" 2 "Catering Process Quality Damaged" 1 "Undefined Error" 0 "No error" ;
VAL_ 3221225472 DIAG_CMD_Cmd 4 "SendGAIN_CLASS_msg" 2 "AbortSelfTest" 1 "SelfTestRequest" 0 "NotApplicable" ;
VAL_ 3221225472 FLIGHT_INFO_FlightPhase 12 "Parking/Post-flight" 11 "Taxi in" 10 "Landing" 9 "Approach" 8 "Cruise" 7 "Climb 2nd step" 6 "Climb 1st step" 5 "Take off 3rd step" 4 "Take off 2nd step" 3 "Take off 1st step" 2 "Taxi out" 1 "Parking/Pre-flight" 0 "NotApplicable" ;
VAL_ 3221225472 STO_Quality 4 "Damaged" 3 "Low" 2 "Medium" 1 "High" 0 "Not applicable" ;
VAL_ 3221225472 STO_Units 13 "Unit/-s" 12 "Lartge Cup/-s" 11 "Medium Cup/-s" 10 "Little Cup/-s" 9 "Flashes" 8 "Meal/-s" 7 "Fluid Ounces" 6 "Pints" 5 "Gallons" 4 "Liter" 3 "Pound" 2 "Ounces" 1 "kg" 0 "NotApplicable" ;
VAL_ 3221225472 CSTA_NewState 9 "StandBy Off" 8 "Error" 7 "Maintenance" 6 "Finished" 2 "StandBy On" ;
VAL_ 3221225472 CMD_Command 22 "Send_GAIN_Class_Msg" 21 "Send_STO_Msg" 20 "Send_CAT_Info_Msg" 4 "Keep warm" 3 "Pause catering process" 2 "Finish catering process" 1 "Start catering process" 0 "Not applicable" ;
VAL_ 2261778437 STA_MGCU_State 4 "Error" 3 "Maintenance" 2 "Operational" ;
